# trimsir_me18 register map
Registers are access not given, no defined reset value unless marked. A register's access mark holds for its fields unless they carry their own. Offsets are from the block's base; lines under a group give offsets from that group; [hi:lo] are bit positions; {n}, {i} and the like mark numbered series; 'fields as' and 'values as' point back to an identical list; <NAME> marks a mode.

## Memory map
0x40005400 TRIMSIR size 0x400 — Trim System Initilazation Registers

## TRIMSIR — Trim System Initilazation Registers
Base 0x40005400
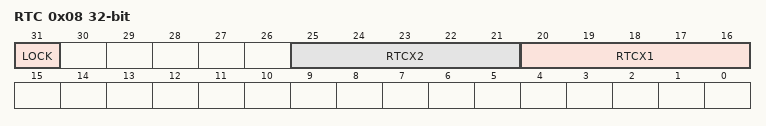
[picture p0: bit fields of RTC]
0x08 RTC — RTC Trim System Initialization Register.
  [31] LOCK
  [25:21] RTCX2 — RTC X2 Trim.
  [20:16] RTCX1 — RTC X1 Trim.
